# PRU_ICSSG0_RAT_SLICE0_CFG_local register map
Vendor: Texas Instruments
Peripheral module from a debugger description file (folder am65x).
Registers are 32-bit, read-only, reset values left out (the file's numbers can be read two ways) unless marked. A register's access mark holds for its fields unless they carry their own. Offsets are as the file gives them; lines under a group give offsets from that group; [hi:lo] are bit positions; {n}, {i} and the like mark numbered series; 'fields as' and 'values as' point back to an identical list; <NAME> marks a mode.

## PRU_ICSSG0_RAT_SLICE0_CFG
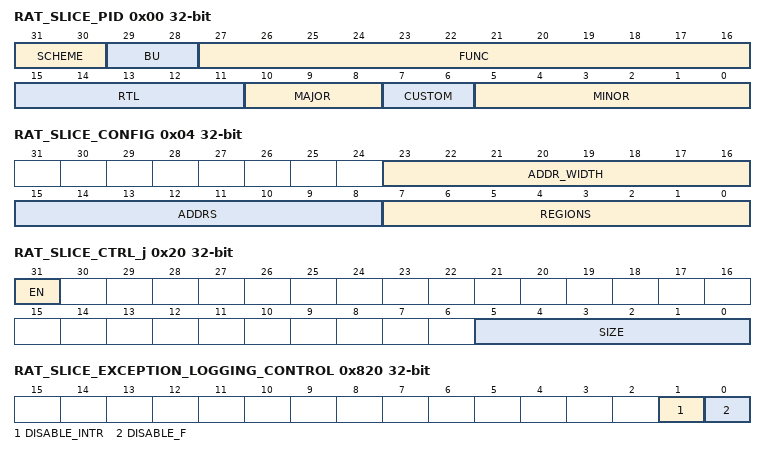
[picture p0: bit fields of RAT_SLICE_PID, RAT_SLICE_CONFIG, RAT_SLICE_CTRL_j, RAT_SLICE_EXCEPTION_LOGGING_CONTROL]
0x00 RAT_SLICE_PID — The Revision Register contains the major and minor revisions for the module.
  [31:30] SCHEME — RAT_SLICE_PID register scheme
  [29:28] BU — Business Unit: 10 = Processors
  [27:16] FUNC — Module ID
  [15:11] RTL — RTL revision. Will vary depending on release.
  [10:8] MAJOR — Major revision
  [7:6] CUSTOM
  [5:0] MINOR — Minor revision
0x04 RAT_SLICE_CONFIG — The Config Register contains the configuration values for the module.
  [23:16] ADDR_WIDTH — Number of address bits
  [15:8] ADDRS — Number of addresses
  [7:0] REGIONS — Number of regions
0x20 RAT_SLICE_CTRL_j rw — The Control for Region a. Offset = 20h + (j * 10h); where j = 0h to 3h
  [31] EN — Enable for the Region
  [5:0] SIZE — Size of the Region in Address Bits. 0 = 1 byte, 1 = 2B, 2 = 4B, 3 = 8B, etc. up to 32 = 4GB.
0x24 RAT_SLICE_BASE_j rw — The Base Address for Region a. This is the source address for matching to a region. Offset = 24h + (j * 10h); where j = 0h to 3h
  [31:0] BASE — Base Address for the Region. It must be aligned to the programmed size.
0x28 RAT_SLICE_TRANS_l_j rw — The Translated Lower Address Bits for Region a. Offset = 28h + (j * 10h); where j = 0h to 3h
  [31:0] LOWER — Translated Lower Address Bits for the Region. It must be aligned to the programmed size.
0x2C RAT_SLICE_TRANS_U_j rw — The Translated Upper Address Bits for Region a. Offset = 2Ch + (j * 10h); where j = 0h to 3h
  [15:0] UPPER — Translated Upper Address Bits for the Region
0x804 RAT_SLICE_DESTINATION_ID rw — The Destination ID Register defines the destination ID value for error messages.
  [7:0] DEST_ID — The destination ID.
0x820 RAT_SLICE_EXCEPTION_LOGGING_CONTROL rw — The Exception Logging Control Register controls the exception logging.
  [1] DISABLE_INTR — Disables logging interrupt when set.
  [0] DISABLE_F — Disables logging when set.
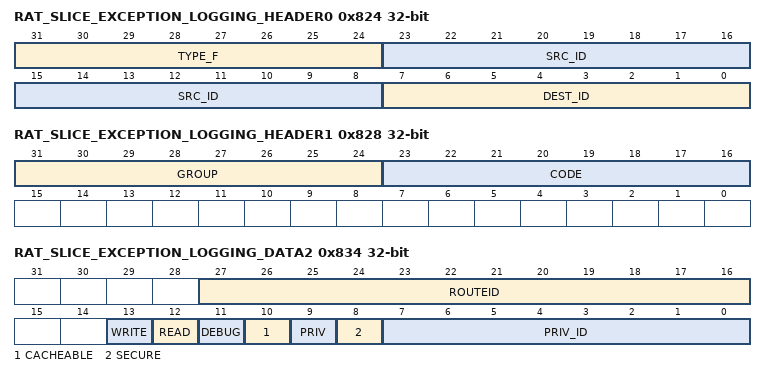
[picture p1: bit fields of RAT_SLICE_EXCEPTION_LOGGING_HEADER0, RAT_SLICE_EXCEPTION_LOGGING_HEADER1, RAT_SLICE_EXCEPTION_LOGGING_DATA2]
0x824 RAT_SLICE_EXCEPTION_LOGGING_HEADER0 — The Exception Logging Header 0 Register contains the first word of the header.
  [31:24] TYPE_F — Type. 4 = RAT.
  [23:8] SRC_ID — Source ID.
  [7:0] DEST_ID — Destination ID.
0x828 RAT_SLICE_EXCEPTION_LOGGING_HEADER1 — The Exception Logging Header 1 Register contains the second word of the header.
  [31:24] GROUP
  [23:16] CODE — Code. 1 = Boundary crossing error.
0x82C RAT_SLICE_EXCEPTION_LOGGING_DATA0 — The Exception Logging Data 0 Register contains the first word of the data.
  [31:0] ADDR_L — Address lower 32 bits.
0x830 RAT_SLICE_EXCEPTION_LOGGING_DATA1 — The Exception Logging Data 1 Register contains the second word of the data.
  [15:0] ADDR_H — Address upper 12 bits.
0x834 RAT_SLICE_EXCEPTION_LOGGING_DATA2 — The Exception Logging Data 2 Register contains the third word of the data.
  [27:16] ROUTEID, [13] WRITE, [12] READ, [11] DEBUG, [10] CACHEABLE, [9] PRIV, [8] SECURE, [7:0] PRIV_ID
0x838 RAT_SLICE_EXCEPTION_LOGGING_DATA3 — The Exception Logging Data 3 Register contains the fourth word of the data. Reading this register will clear the error pending bit.
  [9:0] BYTECNT — Byte count.
0x840 RAT_SLICE_EXCEPTION_PEND_SET access not given — The Exception Logging Interrupt Pending Set Register allows to set the pend signal.
  [0] PEND_SET — Write a 1 to set the exception pend signal. (access RW1S)
0x844 RAT_SLICE_EXCEPTION_PEND_CLEAR access not given — The Exception Logging Interrupt Pending Clear Register allows to clear the pend signal.
  [0] PEND_CLR — Write a 1 to clear the exception pend signal. (access RW1C)
0x848 RAT_SLICE_EXCEPTION_ENABLE_SET access not given — The Exception Logging Interrupt Enable Set Register allows to set the interrupt enable signal.
  [0] ENABLE_SET — Write a 1 to set the exception interrupt enable signal. (access RW1S)
0x84C RAT_SLICE_EXCEPTION_ENABLE_CLEAR access not given — The Exception Logging Interrupt Enable Clear Register allows to clear the interrupt enable signal.
  [0] ENABLE_CLR — Write a 1 to clear the exception interrupt enable signal. (access RW1C)
0x850 RAT_SLICE_EOI_REG rw — EOI Register The EOI register is used to re-trigger the pulse interrupt signal to ensure that any nested interrupt events are serviced. The software interrupt handler must write to the EOI register at the end of the current interrupt processing routine, so that new events can re-trigger the pulse interrupt signal again. For level interrupt signals the EOI register is not functional and must not be used.
  [15:0] EOI_WR — EOI Register
